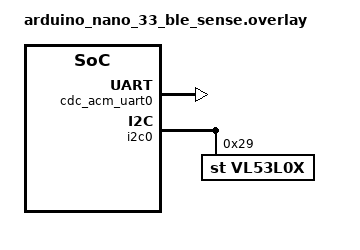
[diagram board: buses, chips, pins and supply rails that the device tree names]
/*
 * Copyright (c) 2021 Nordic Semiconductor ASA
 *
 * SPDX-License-Identifier: Apache-2.0
 */

/ {
	chosen {
		zephyr,console = &cdc_acm_uart0;
	};
};

&zephyr_udc0 {
	cdc_acm_uart0: cdc_acm_uart0 {
		compatible = "zephyr,cdc-acm-uart";
		label = "CDC_ACM_0";
	};
};


&i2c0 {
        status = "okay";
        vl53l0x@29 {
                compatible = "st,vl53l0x";
                reg = <0x29>;
                label = "VL53L0X";
        };
};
